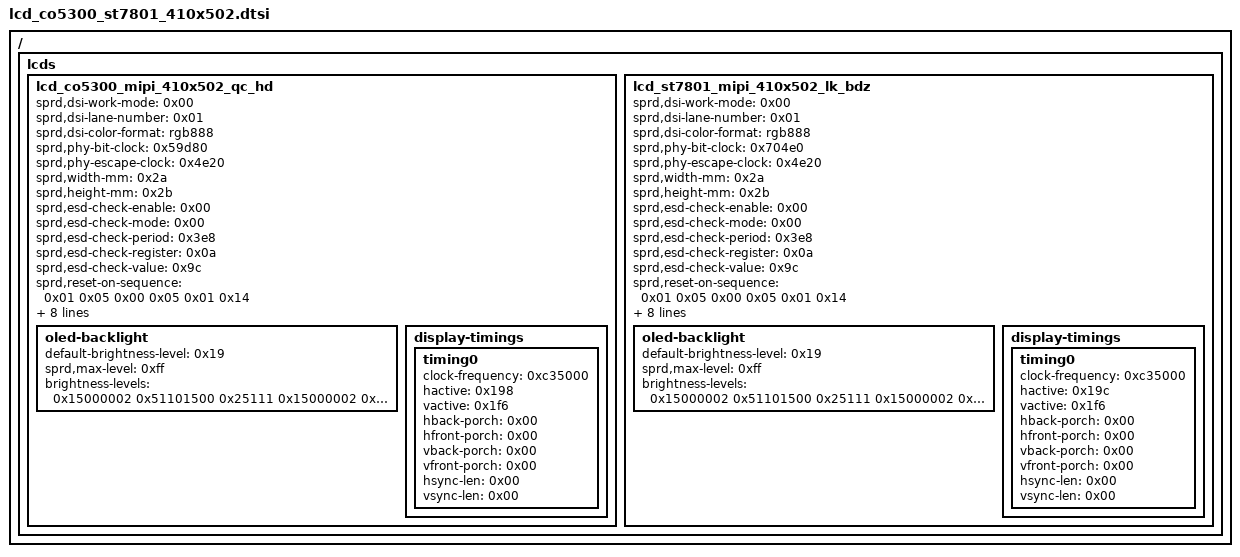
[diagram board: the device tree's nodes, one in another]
/*
 * CO5300 / ST7801 410x502 panel config extracted from real W527/UWS6152 device DTB
 * Source: Backup/dtb.bin -> stock_uws6152.dts (spd_dump -> dtc decompile)
 * Reference repo (cd12m_ref) used only for driver behavior, not device tree.
 */
/ { lcds {
	lcd_co5300_mipi_410x502_qc_hd {
			sprd,dsi-work-mode = <0x00>;
			sprd,dsi-lane-number = <0x01>;
			sprd,dsi-color-format = "rgb888";
			sprd,phy-bit-clock = <0x59d80>;
			sprd,phy-escape-clock = <0x4e20>;
			sprd,width-mm = <0x2a>;
			sprd,height-mm = <0x2b>;
			sprd,esd-check-enable = <0x00>;
			sprd,esd-check-mode = <0x00>;
			sprd,esd-check-period = <0x3e8>;
			sprd,esd-check-register = <0x0a>;
			sprd,esd-check-value = <0x9c>;
			sprd,reset-on-sequence = <0x01 0x05 0x00 0x05 0x01 0x14>;
			sprd,reset-off-sequence = <0x01 0x05>;
			sprd,use-dcs-write;
			sprd,initial-command = [15 00 00 02 fe 00 15 00 00 02 3a 77 15 00 00 02 35 00 15 00 00 02 53 20 15 00 00 02 51 00 15 00 00 02 63 ff 39 00 00 05 2a 00 16 01 ad 39 00 00 05 2b 00 00 01 f5 39 00 00 05 31 00 16 01 ad 39 00 00 05 30 00 00 01 f5 05 00 00 01 12 05 78 00 01 11 05 32 00 01 29];
			sprd,sleep-in-command = [15 32 00 01 28 15 78 00 01 10];
			sprd,sleep-out-command = [15 78 00 01 11 15 32 00 01 29];
			phandle = <0x148>;

			oled-backlight {
				default-brightness-level = <0x19>;
				sprd,max-level = <0xff>;
				brightness-levels = <0x15000002 0x51101500 0x25111 0x15000002 0x51121500 0x25113 0x15000002 0x51141500 0x25115 0x15000002 0x51161500 0x25117 0x15000002 0x51181500 0x25119 0x15000002 0x511a1500 0x2511b 0x15000002 0x511c1500 0x2511d 0x15000002 0x511e1500 0x2511f 0x15000002 0x51201500 0x25121 0x15000002 0x51221500 0x25123 0x15000002 0x51241500 0x25125 0x15000002 0x51261500 0x25127 0x15000002 0x51281500 0x25129 0x15000002 0x512a1500 0x2512b 0x15000002 0x512c1500 0x2512d 0x15000002 0x512e1500 0x2512f 0x15000002 0x51301500 0x25131 0x15000002 0x51321500 0x25133 0x15000002 0x51341500 0x25135 0x15000002 0x51361500 0x25137 0x15000002 0x51381500 0x25139 0x15000002 0x513a1500 0x2513b 0x15000002 0x513c1500 0x2513d 0x15000002 0x513e1500 0x2513f 0x15000002 0x51401500 0x25141 0x15000002 0x51421500 0x25143 0x15000002 0x51441500 0x25145 0x15000002 0x51461500 0x25147 0x15000002 0x51481500 0x25149 0x15000002 0x514a1500 0x2514b 0x15000002 0x514c1500 0x2514d 0x15000002 0x514e1500 0x2514f 0x15000002 0x51501500 0x25151 0x15000002 0x51521500 0x25153 0x15000002 0x51541500 0x25155 0x15000002 0x51561500 0x25157 0x15000002 0x51581500 0x25159 0x15000002 0x515a1500 0x2515b 0x15000002 0x515c1500 0x2515d 0x15000002 0x515e1500 0x2515f 0x15000002 0x51601500 0x25161 0x15000002 0x51621500 0x25163 0x15000002 0x51641500 0x25165 0x15000002 0x51661500 0x25167 0x15000002 0x51681500 0x25169 0x15000002 0x516a1500 0x2516b 0x15000002 0x516c1500 0x2516d 0x15000002 0x516e1500 0x2516f 0x15000002 0x51701500 0x25171 0x15000002 0x51721500 0x25173 0x15000002 0x51741500 0x25175 0x15000002 0x51761500 0x25177 0x15000002 0x51781500 0x25179 0x15000002 0x517a1500 0x2517b 0x15000002 0x517c1500 0x2517d 0x15000002 0x517e1500 0x2517f 0x15000002 0x51801500 0x25181 0x15000002 0x51821500 0x25183 0x15000002 0x51841500 0x25185 0x15000002 0x51861500 0x25187 0x15000002 0x51881500 0x25189 0x15000002 0x518a1500 0x2518b 0x15000002 0x518c1500 0x2518d 0x15000002 0x518e1500 0x2518f 0x15000002 0x51901500 0x25191 0x15000002 0x51921500 0x25193 0x15000002 0x51941500 0x25195 0x15000002 0x51961500 0x25197 0x15000002 0x51981500 0x25199 0x15000002 0x519a1500 0x2519b 0x15000002 0x519c1500 0x2519d 0x15000002 0x519e1500 0x2519f 0x15000002 0x51a01500 0x251a1 0x15000002 0x51a21500 0x251a3 0x15000002 0x51a41500 0x251a5 0x15000002 0x51a61500 0x251a7 0x15000002 0x51a81500 0x251a9 0x15000002 0x51aa1500 0x251ab 0x15000002 0x51ac1500 0x251ad 0x15000002 0x51ae1500 0x251af 0x15000002 0x51b01500 0x251b1 0x15000002 0x51b21500 0x251b3 0x15000002 0x51b41500 0x251b5 0x15000002 0x51b61500 0x251b7 0x15000002 0x51b81500 0x251b9 0x15000002 0x51ba1500 0x251bb 0x15000002 0x51bc1500 0x251bd 0x15000002 0x51be1500 0x251bf 0x15000002 0x51c01500 0x251c1 0x15000002 0x51c21500 0x251c3 0x15000002 0x51c41500 0x251c5 0x15000002 0x51c61500 0x251c7 0x15000002 0x51c81500 0x251c9 0x15000002 0x51ca1500 0x251cb 0x15000002 0x51cc1500 0x251cd 0x15000002 0x51ce1500 0x251cf 0x15000002 0x51d01500 0x251d1 0x15000002 0x51d21500 0x251d3 0x15000002 0x51d41500 0x251d5 0x15000002 0x51d61500 0x251d7 0x15000002 0x51d81500 0x251d9 0x15000002 0x51da1500 0x251db 0x15000002 0x51dc1500 0x251dd 0x15000002 0x51de1500 0x251df 0x15000002 0x51e01500 0x251e1 0x15000002 0x51e21500 0x251e3 0x15000002 0x51e41500 0x251e5 0x15000002 0x51e61500 0x251e7 0x15000002 0x51e81500 0x251e9 0x15000002 0x51ea1500 0x251eb 0x15000002 0x51ec1500 0x251ed 0x15000002 0x51ee1500 0x251ef 0x15000002 0x51f01500 0x251f1 0x15000002 0x51f21500 0x251f3 0x15000002 0x51f41500 0x251f5 0x15000002 0x51f61500 0x251f7 0x15000002 0x51f81500 0x251f9 0x15000002 0x51fa1500 0x251fb 0x15000002 0x51fc1500 0x251fd 0x15000002 0x51fe1500 0x251ff 0x15000002 0x51ff1500 0x251ff 0x15000002 0x51ff1500 0x251ff 0x15000002 0x51ff1500 0x251ff 0x15000002 0x51ff1500 0x251ff 0x15000002 0x51ff1500 0x251ff 0x15000002 0x51ff1500 0x251ff 0x15000002 0x51ff1500 0x251ff 0x15000002 0x51ff1500 0x251ff>;
			};

			display-timings {

				timing0 {
					clock-frequency = <0xc35000>;
					hactive = <0x198>;
					vactive = <0x1f6>;
					hback-porch = <0x00>;
					hfront-porch = <0x00>;
					vback-porch = <0x00>;
					vfront-porch = <0x00>;
					hsync-len = <0x00>;
					vsync-len = <0x00>;
				};
			};
		};

	lcd_st7801_mipi_410x502_lk_bdz {
			sprd,dsi-work-mode = <0x00>;
			sprd,dsi-lane-number = <0x01>;
			sprd,dsi-color-format = "rgb888";
			sprd,phy-bit-clock = <0x704e0>;
			sprd,phy-escape-clock = <0x4e20>;
			sprd,width-mm = <0x2a>;
			sprd,height-mm = <0x2b>;
			sprd,esd-check-enable = <0x00>;
			sprd,esd-check-mode = <0x00>;
			sprd,esd-check-period = <0x3e8>;
			sprd,esd-check-register = <0x0a>;
			sprd,esd-check-value = <0x9c>;
			sprd,reset-on-sequence = <0x01 0x05 0x00 0x05 0x01 0x14>;
			sprd,reset-off-sequence = <0x01 0x05>;
			sprd,use-dcs-write;
			sprd,initial-command = [15 78 00 02 11 00 15 00 00 02 53 20 15 00 00 02 51 00 15 00 00 02 3a 77 15 00 00 02 35 00 39 00 00 05 2a 00 00 01 9b 39 00 00 05 2b 00 00 01 f5 15 78 00 02 29 00];
			sprd,sleep-in-command = [15 32 00 01 28 15 78 00 01 10];
			sprd,sleep-out-command = [15 78 00 01 11 15 32 00 01 29];
			phandle = <0x149>;

			oled-backlight {
				default-brightness-level = <0x19>;
				sprd,max-level = <0xff>;
				brightness-levels = <0x15000002 0x51101500 0x25111 0x15000002 0x51121500 0x25113 0x15000002 0x51141500 0x25115 0x15000002 0x51161500 0x25117 0x15000002 0x51181500 0x25119 0x15000002 0x511a1500 0x2511b 0x15000002 0x511c1500 0x2511d 0x15000002 0x511e1500 0x2511f 0x15000002 0x51201500 0x25121 0x15000002 0x51221500 0x25123 0x15000002 0x51241500 0x25125 0x15000002 0x51261500 0x25127 0x15000002 0x51281500 0x25129 0x15000002 0x512a1500 0x2512b 0x15000002 0x512c1500 0x2512d 0x15000002 0x512e1500 0x2512f 0x15000002 0x51301500 0x25131 0x15000002 0x51321500 0x25133 0x15000002 0x51341500 0x25135 0x15000002 0x51361500 0x25137 0x15000002 0x51381500 0x25139 0x15000002 0x513a1500 0x2513b 0x15000002 0x513c1500 0x2513d 0x15000002 0x513e1500 0x2513f 0x15000002 0x51401500 0x25141 0x15000002 0x51421500 0x25143 0x15000002 0x51441500 0x25145 0x15000002 0x51461500 0x25147 0x15000002 0x51481500 0x25149 0x15000002 0x514a1500 0x2514b 0x15000002 0x514c1500 0x2514d 0x15000002 0x514e1500 0x2514f 0x15000002 0x51501500 0x25151 0x15000002 0x51521500 0x25153 0x15000002 0x51541500 0x25155 0x15000002 0x51561500 0x25157 0x15000002 0x51581500 0x25159 0x15000002 0x515a1500 0x2515b 0x15000002 0x515c1500 0x2515d 0x15000002 0x515e1500 0x2515f 0x15000002 0x51601500 0x25161 0x15000002 0x51621500 0x25163 0x15000002 0x51641500 0x25165 0x15000002 0x51661500 0x25167 0x15000002 0x51681500 0x25169 0x15000002 0x516a1500 0x2516b 0x15000002 0x516c1500 0x2516d 0x15000002 0x516e1500 0x2516f 0x15000002 0x51701500 0x25171 0x15000002 0x51721500 0x25173 0x15000002 0x51741500 0x25175 0x15000002 0x51761500 0x25177 0x15000002 0x51781500 0x25179 0x15000002 0x517a1500 0x2517b 0x15000002 0x517c1500 0x2517d 0x15000002 0x517e1500 0x2517f 0x15000002 0x51801500 0x25181 0x15000002 0x51821500 0x25183 0x15000002 0x51841500 0x25185 0x15000002 0x51861500 0x25187 0x15000002 0x51881500 0x25189 0x15000002 0x518a1500 0x2518b 0x15000002 0x518c1500 0x2518d 0x15000002 0x518e1500 0x2518f 0x15000002 0x51901500 0x25191 0x15000002 0x51921500 0x25193 0x15000002 0x51941500 0x25195 0x15000002 0x51961500 0x25197 0x15000002 0x51981500 0x25199 0x15000002 0x519a1500 0x2519b 0x15000002 0x519c1500 0x2519d 0x15000002 0x519e1500 0x2519f 0x15000002 0x51a01500 0x251a1 0x15000002 0x51a21500 0x251a3 0x15000002 0x51a41500 0x251a5 0x15000002 0x51a61500 0x251a7 0x15000002 0x51a81500 0x251a9 0x15000002 0x51aa1500 0x251ab 0x15000002 0x51ac1500 0x251ad 0x15000002 0x51ae1500 0x251af 0x15000002 0x51b01500 0x251b1 0x15000002 0x51b21500 0x251b3 0x15000002 0x51b41500 0x251b5 0x15000002 0x51b61500 0x251b7 0x15000002 0x51b81500 0x251b9 0x15000002 0x51ba1500 0x251bb 0x15000002 0x51bc1500 0x251bd 0x15000002 0x51be1500 0x251bf 0x15000002 0x51c01500 0x251c1 0x15000002 0x51c21500 0x251c3 0x15000002 0x51c41500 0x251c5 0x15000002 0x51c61500 0x251c7 0x15000002 0x51c81500 0x251c9 0x15000002 0x51ca1500 0x251cb 0x15000002 0x51cc1500 0x251cd 0x15000002 0x51ce1500 0x251cf 0x15000002 0x51d01500 0x251d1 0x15000002 0x51d21500 0x251d3 0x15000002 0x51d41500 0x251d5 0x15000002 0x51d61500 0x251d7 0x15000002 0x51d81500 0x251d9 0x15000002 0x51da1500 0x251db 0x15000002 0x51dc1500 0x251dd 0x15000002 0x51de1500 0x251df 0x15000002 0x51e01500 0x251e1 0x15000002 0x51e21500 0x251e3 0x15000002 0x51e41500 0x251e5 0x15000002 0x51e61500 0x251e7 0x15000002 0x51e81500 0x251e9 0x15000002 0x51ea1500 0x251eb 0x15000002 0x51ec1500 0x251ed 0x15000002 0x51ee1500 0x251ef 0x15000002 0x51f01500 0x251f1 0x15000002 0x51f21500 0x251f3 0x15000002 0x51f41500 0x251f5 0x15000002 0x51f61500 0x251f7 0x15000002 0x51f81500 0x251f9 0x15000002 0x51fa1500 0x251fb 0x15000002 0x51fc1500 0x251fd 0x15000002 0x51fe1500 0x251ff 0x15000002 0x51ff1500 0x251ff 0x15000002 0x51ff1500 0x251ff 0x15000002 0x51ff1500 0x251ff 0x15000002 0x51ff1500 0x251ff 0x15000002 0x51ff1500 0x251ff 0x15000002 0x51ff1500 0x251ff 0x15000002 0x51ff1500 0x251ff 0x15000002 0x51ff1500 0x251ff>;
			};

			display-timings {

				timing0 {
					clock-frequency = <0xc35000>;
					hactive = <0x19c>;
					vactive = <0x1f6>;
					hback-porch = <0x00>;
					hfront-porch = <0x00>;
					vback-porch = <0x00>;
					vfront-porch = <0x00>;
					hsync-len = <0x00>;
					vsync-len = <0x00>;
				};
			};
		};
}; };
